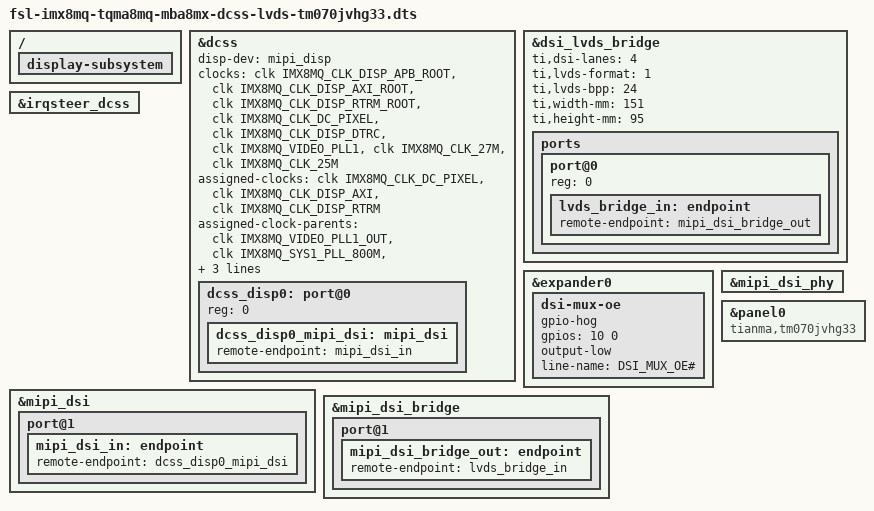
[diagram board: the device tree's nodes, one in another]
/*
 * Copyright 2019 TQ Systems GmbH
 *
 * This program is free software; you can redistribute it and/or
 * modify it under the terms of the GNU General Public License
 * as published by the Free Software Foundation; either version 2
 * of the License, or (at your option) any later version.
 *
 * This program is distributed in the hope that it will be useful,
 * but WITHOUT ANY WARRANTY; without even the implied warranty of
 * MERCHANTABILITY or FITNESS FOR A PARTICULAR PURPOSE.  See the
 * GNU General Public License for more details.
 */

#include "fsl-imx8mq-tqma8mq-mba8mx.dts"

/ {
	display-subsystem {
		status = "okay";
	};
};

&dcss {
	status = "okay";
	disp-dev = "mipi_disp";

	clocks = <&clk IMX8MQ_CLK_DISP_APB_ROOT>,
		 <&clk IMX8MQ_CLK_DISP_AXI_ROOT>,
		 <&clk IMX8MQ_CLK_DISP_RTRM_ROOT>,
		 <&clk IMX8MQ_CLK_DC_PIXEL>,
		 <&clk IMX8MQ_CLK_DISP_DTRC>,
		 <&clk IMX8MQ_VIDEO_PLL1>,
		 <&clk IMX8MQ_CLK_27M>,
		 <&clk IMX8MQ_CLK_25M>;
	clock-names = "apb", "axi", "rtrm", "pix", "dtrc", "pll",
		      "pll_src1", "pll_src2";

	assigned-clocks = <&clk IMX8MQ_CLK_DC_PIXEL>,
			  <&clk IMX8MQ_CLK_DISP_AXI>,
			  <&clk IMX8MQ_CLK_DISP_RTRM>;
	assigned-clock-parents = <&clk IMX8MQ_VIDEO_PLL1_OUT>,
				 <&clk IMX8MQ_SYS1_PLL_800M>,
				 <&clk IMX8MQ_SYS1_PLL_800M>;
	assigned-clock-rates = <600000000>,
			       <800000000>,
			       <400000000>;

	dcss_disp0: port@0 {
		reg = <0>;

		dcss_disp0_mipi_dsi: mipi_dsi {
			remote-endpoint = <&mipi_dsi_in>;
		};
	};
};

/* input port of HDMI, linked to dcss in CPU tree */
/delete-node/ &hdmi_disp;
/* output port of DCSS, need to overwrite */
/delete-node/ &dcss_disp0_hdmi;

&dsi_lvds_bridge {
	ti,dsi-lanes = <4>;
	ti,lvds-format = <1>;
	ti,lvds-bpp = <24>;
	ti,width-mm = <151>;
	ti,height-mm = <95>;
	status = "okay";

	ports {
		#address-cells = <1>;
		#size-cells = <0>;

		port@0 {
			reg = <0>;

			lvds_bridge_in: endpoint {
				remote-endpoint = <&mipi_dsi_bridge_out>;
			};
		};
	};
};

&expander0 {
	dsi-mux-oe {
		gpio-hog;
		gpios = <10 0>;
		output-low;
		line-name = "DSI_MUX_OE#";
	};
};

&irqsteer_dcss {
	status = "okay";
};

&mipi_dsi {
	status = "okay";

	port@1 {
		mipi_dsi_in: endpoint {
			remote-endpoint = <&dcss_disp0_mipi_dsi>;
		};
	};

};

&mipi_dsi_bridge {
	status = "okay";

	port@1 {
		mipi_dsi_bridge_out: endpoint {
			remote-endpoint = <&lvds_bridge_in>;
		};
	};
};

&mipi_dsi_phy {
	status = "okay";
};

&panel0 {
	compatible = "tianma,tm070jvhg33";
	status = "okay";
};
